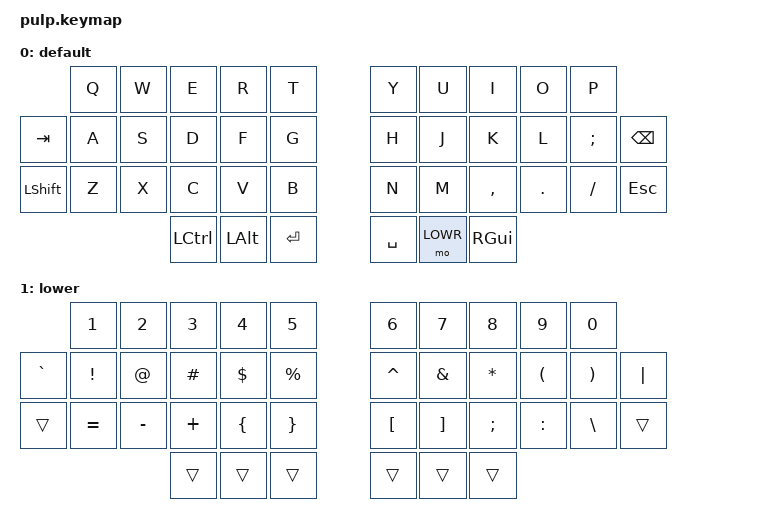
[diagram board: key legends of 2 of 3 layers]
#include <behaviors.dtsi>
#include <dt-bindings/zmk/keys.h>
#include <dt-bindings/zmk/bt.h>

#define BASE 0
#define LOWR 1
#define BT 2

/ {
    combos {
        compatible = "zmk,combos";

        bt_layer {
            timeout-ms = <100>;
            key-positions = <34 35 38>;
            bindings = <&tog BT>;
        };
    };


    keymap {
        compatible = "zmk,keymap";


        default_layer {
            display-name = "default";
            // ------------------------------------------------------------------------------------------------------------
            // |       |  Q  |  W  |  E   |  R   |  T   |                   |  Y   |  U    |  I    |  O   |   P   |       |
            // |  TAB  |  A  |  S  |  D   |  F   |  G   |                   |  H   |  J    |  K    |  L   |   ;   |  BSPC |
            // | SHIFT |  Z  |  X  |  C   |  V   |  B   |                   |  N   |  M    |  ,    |  .   |   /   | ESC   |
            //                     | CTRL  | ALT | ENTER|                   | SPACE| LOWER  |  GUI  |
                        bindings = <
                      &kp Q  &kp W    &kp E    &kp R     &kp T                &kp Y  &kp U     &kp I     &kp O    &kp P
            &kp TAB   &kp A  &kp S    &kp D    &kp F     &kp G                &kp H  &kp J     &kp K     &kp L    &kp SEMI &kp BSPC
            &kp LSHFT &kp Z  &kp X    &kp C    &kp V     &kp B                &kp N  &kp M     &kp COMMA &kp DOT  &kp FSLH &kp ESC
                                   &kp LCTRL &kp LALT  &kp RET                &kp SPACE  &mo LOWR  &kp RGUI
                        >;

            sensor-bindings = <&inc_dec_kp C_VOL_UP C_VOL_DN &inc_dec_kp PG_UP PG_DN>;
        };


        lower_layer {
            display-name = "lower";
            // ------------------------------------------------------------------------------------------------------------
            // |       |  1  |  2  |  3   |  4   |  5   |                   |  6   |  7    |  8    |  9   |   0   |       |
            // |   `   |  !  |  @  |  #   |  $   |  %   |                   |  ^   |  &    |  *    |  (   |   )   |   |   |
            // |       |  =  |  -  |  +   |  {   |  }   |                   |  [   |  ]    |  ;    |  :   |   \   |       |
            //               |     |      |      |      |                   |      |       |       |      |
                        bindings = <
                        &kp N1    &kp N2    &kp N3      &kp N4    &kp N5                       &kp N6    &kp N7   &kp N8    &kp N9    &kp N0
            &kp GRAVE   &kp EXCL  &kp AT    &kp HASH    &kp DLLR  &kp PRCNT                    &kp CARET &kp AMPS &kp ASTRK &kp LPAR  &kp RPAR  &kp PIPE
            &trans      &kp EQUAL &kp MINUS &kp PLUS    &kp LBRC  &kp RBRC                     &kp LBKT  &kp RBKT &kp SEMI  &kp COLON &kp BSLH  &trans
                                            &trans      &trans    &trans                       &trans   &trans    &trans
                        >;

                        sensor-bindings = <&inc_dec_kp C_VOL_UP C_VOL_DN &inc_dec_kp PG_UP PG_DN>;
        };

        bt_layer {
            display-name = "Bluetooth";

            // ------------------------------------------------------------------------------------------------------------
            // | BT CLR | BT 0 | BT 1 | BT 2 | BT 3 | BT 4 |             | BT NXT | BT PRV |       |       |       |       |
            // |        |      |      |      |      |      |             |        |        |       |       |       |       |
            // |        |      |      |      |      |      |             |        |        |       |       |       |       |
            //                      |       |       |       |             |       |        |       |
            // ------------------------------------------------------------------------------------------------------------

            bindings = <
                &bt BT_CLR    &bt BT_SEL 0  &bt BT_SEL 1  &bt BT_SEL 2  &bt BT_SEL 3  &bt BT_SEL 4
                &bt BT_NXT    &bt BT_PRV     &trans       &trans       &trans       &trans
                &trans        &trans         &trans       &trans       &trans       &trans

                                      &trans       &trans       &trans
                                      &trans       &trans       &trans
            >;

            sensor-bindings = <&inc_dec_kp C_VOL_UP C_VOL_DN &inc_dec_kp PG_UP PG_DN>;
        };

    };
};
